# MSPM0G150X register map
Vendor: Texas Instruments; File version: This preliminary header file does not have a version number - build date: 2023-02-21 16:25:48
CPU: CM0 r0p1, little endian, MPU, no FPU, 3 interrupt priority bits
Registers are 32-bit, read-write, reset 0x0 unless marked. A register's access mark holds for its fields unless they carry their own. Offsets are from the block's base; [hi:lo] are bit positions.

## TRNG — PERIPHERALREGION
Base 0x40444000
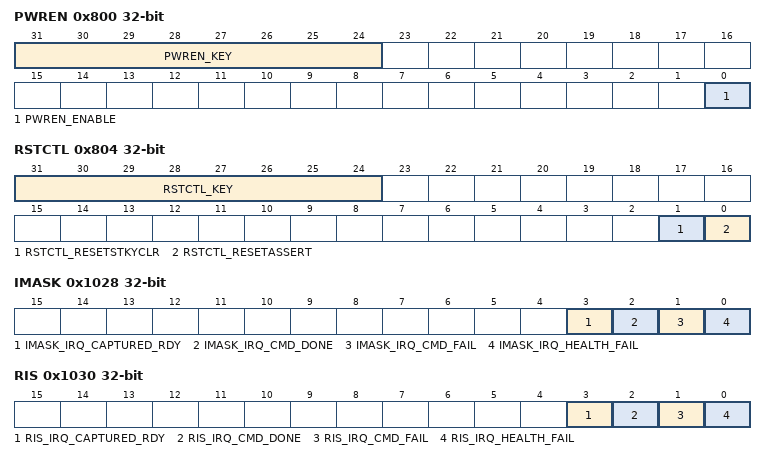
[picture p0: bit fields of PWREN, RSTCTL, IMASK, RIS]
0x800 PWREN — Power enable
  [31:24] PWREN_KEY wo — KEY to allow Power State Change
    38=PWREN_KEY_UNLOCK_W (_TO_UNLOCK_W_)
  [0] PWREN_ENABLE — Enable the power
    0=PWREN_ENABLE_DISABLE (DISABLE); 1=PWREN_ENABLE_ENABLE (ENABLE)
0x804 RSTCTL wo — Reset Control
  [31:24] RSTCTL_KEY — Unlock key
    177=RSTCTL_KEY_UNLOCK_W (_TO_UNLOCK_W_)
  [1] RSTCTL_RESETSTKYCLR — Clear the RESETSTKY bit in the STAT register
    0=RSTCTL_RESETSTKYCLR_NOP (NOP); 1=RSTCTL_RESETSTKYCLR_CLR (CLR)
  [0] RSTCTL_RESETASSERT — Assert reset to the peripheral
    0=RSTCTL_RESETASSERT_NOP (NOP); 1=RSTCTL_RESETASSERT_ASSERT (ASSERT)
0x814 GPRCM_STAT ro — Status Register
  [16] GPRCM_STAT_RESETSTKY — This bit indicates, if the peripheral was reset, since this bit was cleared by RESETSTKYCLR in the RSTCTL register
    0=GPRCM_STAT_RESETSTKY_NORES (NORES); 1=GPRCM_STAT_RESETSTKY_RESET (RESET)
0x1020 IIDX ro — Interrupt index
  [7:0] IIDX_STAT — Interrupt index status
    0=IIDX_STAT_NO_INTR (NO_INTR); 1=IIDX_STAT_IRQ_HEALTH_FAIL (IRQ_HEALTH_FAIL); 2=IIDX_STAT_IRQ_CMD_FAIL (IRQ_CMD_FAIL); 3=IIDX_STAT_IRQ_CMD_DONE (IRQ_CMD_DONE); 4=IIDX_STAT_IRQ_CAPTURED_RDY (IRQ_CAPTURED_RDY)
0x1028 IMASK — Interrupt mask
  [3] IMASK_IRQ_CAPTURED_RDY — Mask for IRQ_CAPTURED_RDY. Indicates to the CPU that the Captured Word is ready to be read.
    0=IMASK_IRQ_CAPTURED_RDY_DISABLED (DISABLED); 1=IMASK_IRQ_CAPTURED_RDY_ENABLED (ENABLED)
  [2] IMASK_IRQ_CMD_DONE — Mask for IRQ_CMD_DONE. Indicates that a command has finished
    0=IMASK_IRQ_CMD_DONE_DISABLED (DISABLED); 1=IMASK_IRQ_CMD_DONE_ENABLED (ENABLED)
  [1] IMASK_IRQ_CMD_FAIL — Masked interrupt source for IRQ_CMD_FAIL. Indicates that the just issued command/mode has been rejected.
    0=IMASK_IRQ_CMD_FAIL_DISABLED (DISABLED); 1=IMASK_IRQ_CMD_FAIL_ENABLED (ENABLED)
  [0] IMASK_IRQ_HEALTH_FAIL — Mask for IRQ_HEALTH_FAIL. Indicates that a health test has failed.
    0=IMASK_IRQ_HEALTH_FAIL_DISABLED (DISABLED); 1=IMASK_IRQ_HEALTH_FAIL_ENABLED (ENABLED)
0x1030 RIS ro — Raw interrupt status
  [3] RIS_IRQ_CAPTURED_RDY — Indicates to the CPU that the Captured Word is ready to be read. Reading the IIDX will clear this interrupt.
    0=RIS_IRQ_CAPTURED_RDY_CLR (CLR); 1=RIS_IRQ_CAPTURED_RDY_SET (SET)
  [2] RIS_IRQ_CMD_DONE — Raw interrupt source for IRQ_CMD_DONE. Indicates that the issued command/mode has completed.
    0=RIS_IRQ_CMD_DONE_CLR (CLR); 1=RIS_IRQ_CMD_DONE_SET (SET)
  [1] RIS_IRQ_CMD_FAIL — Masked interrupt source for IRQ_CMD_FAIL. Indicates that the just issued command/mode has been rejected.
    0=RIS_IRQ_CMD_FAIL_CLR (CLR); 1=RIS_IRQ_CMD_FAIL_SET (SET)
  [0] RIS_IRQ_HEALTH_FAIL — Indicates to the CPU that any of the health tests have failed. Reading the IIDX will clear this interrupt.
    0=RIS_IRQ_HEALTH_FAIL_CLR (CLR); 1=RIS_IRQ_HEALTH_FAIL_SET (SET)
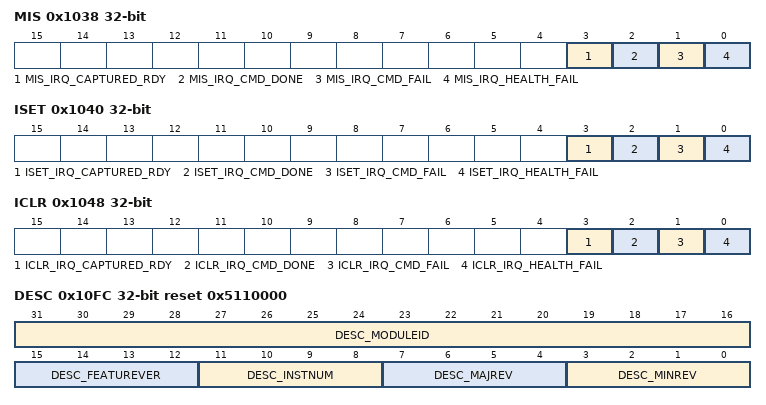
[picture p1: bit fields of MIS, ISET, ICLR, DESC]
0x1038 MIS ro — Masked interrupt status
  [3] MIS_IRQ_CAPTURED_RDY — Masked interrupt result for CAPTURED_READY. Indicates to the CPU that the Captured Word is ready to be read. Reading the IIDX will clear this interrupt.
    0=MIS_IRQ_CAPTURED_RDY_CLR (CLR); 1=MIS_IRQ_CAPTURED_RDY_SET (SET)
  [2] MIS_IRQ_CMD_DONE — Masked interrupt source for IRQ_CMD_DONE. Indicates that the issued command/mode has completed.
    0=MIS_IRQ_CMD_DONE_CLR (CLR); 1=MIS_IRQ_CMD_DONE_SET (SET)
  [1] MIS_IRQ_CMD_FAIL — Masked interrupt source for IRQ_CMD_FAIL. Indicates that the just issued command/mode has been rejected.
    0=MIS_IRQ_CMD_FAIL_CLR (CLR); 1=MIS_IRQ_CMD_FAIL_SET (SET)
  [0] MIS_IRQ_HEALTH_FAIL — Masked interrupt result for HEALTH_FAIL. Indicates to the CPU that any of the health tests have failed for the latest 1024-bit window.
    0=MIS_IRQ_HEALTH_FAIL_CLR (CLR); 1=MIS_IRQ_HEALTH_FAIL_SET (SET)
0x1040 ISET wo — Interrupt set
  [3] ISET_IRQ_CAPTURED_RDY — Indicates to the CPU that the Captured Word is ready to be read. Reading the IIDX or DATA_CAPTURE registers will clear this interrupt.
    0=ISET_IRQ_CAPTURED_RDY_NO_EFFECT (NO_EFFECT); 1=ISET_IRQ_CAPTURED_RDY_SET (SET)
  [2] ISET_IRQ_CMD_DONE — Write to turn on CMD_DONE IRQ. Indicates that the last issued TRNG command has finished.
    0=ISET_IRQ_CMD_DONE_NO_EFFECT (NO_EFFECT); 1=ISET_IRQ_CMD_DONE_SET (SET)
  [1] ISET_IRQ_CMD_FAIL — Masked interrupt source for IRQ_CMD_FAIL. Indicates that the just issued command/mode has been rejected.
    0=ISET_IRQ_CMD_FAIL_NO_EFFECT (NO_EFFECT); 1=ISET_IRQ_CMD_FAIL_SET (SET)
  [0] ISET_IRQ_HEALTH_FAIL — Indicates to the CPU that any of the health tests have failed. Reading the IIDX or DATA_CAPTURE registers will clear this interrupt.
    0=ISET_IRQ_HEALTH_FAIL_NO_EFFECT (NO_EFFECT); 1=ISET_IRQ_HEALTH_FAIL_SET (SET)
0x1048 ICLR wo — Interrupt clear
  [3] ICLR_IRQ_CAPTURED_RDY — Indicates to the CPU that the Captured Word is ready to be read. Reading the IIDX or DATA_CAPTURE registers will clear this interrupt.
    0=ICLR_IRQ_CAPTURED_RDY_NO_EFFECT (NO_EFFECT); 1=ICLR_IRQ_CAPTURED_RDY_CLR (CLR)
  [2] ICLR_IRQ_CMD_DONE — Write to turn off CMD_DONE IRQ. Indicates that the last issued TRNG command has finished.
    0=ICLR_IRQ_CMD_DONE_NO_EFFECT (NO_EFFECT); 1=ICLR_IRQ_CMD_DONE_CLR (CLR)
  [1] ICLR_IRQ_CMD_FAIL — Masked interrupt source for IRQ_CMD_FAIL. Indicates that the just issued command/mode has been rejected.
    0=ICLR_IRQ_CMD_FAIL_NO_EFFECT (NO_EFFECT); 1=ICLR_IRQ_CMD_FAIL_CLR (CLR)
  [0] ICLR_IRQ_HEALTH_FAIL — Indicates to the CPU that any of the health tests have failed. Reading the IIDX or DATA_CAPTURE registers will clear this interrupt.
    0=ICLR_IRQ_HEALTH_FAIL_NO_EFFECT (NO_EFFECT); 1=ICLR_IRQ_HEALTH_FAIL_CLR (CLR)
0x10FC DESC ro reset 0x5110000 — Module descriptions
  [31:16] DESC_MODULEID — Module Identifier - An internal TI page has been created to request unique module IDs
  [15:12] DESC_FEATUREVER — Feature Set for the module *instance*
  [11:8] DESC_INSTNUM — Instance Number within the device. This will be a parameter to the RTL for modules that can have multiple instances
  [7:4] DESC_MAJREV — Major rev of the IP
  [3:0] DESC_MINREV — Minor rev of the IP
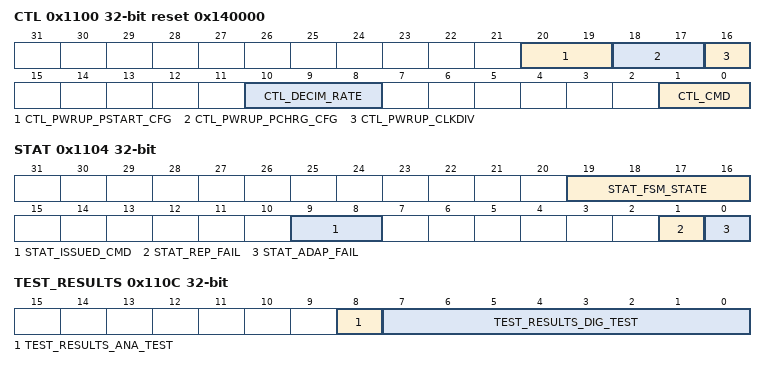
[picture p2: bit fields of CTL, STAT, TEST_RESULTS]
0x1100 CTL reset 0x140000 — Controls the command and decimation rate
  [20:19] CTL_PWRUP_PSTART_CFG — Configure pusle startup sequence length b00 = Disabled b01 = rise at 10us, fall at 50us b10 = rise at 10us, fall at 70us (default) b11 = rise at 10us, fall at 90us
  [18:17] CTL_PWRUP_PCHRG_CFG — Configure PCHARGE sequence length b00 = Disabled b01 = 20 us PCHARGE b10 = 30 us PCHARGE (default) b11 = 40 us PCHARGE
  [16] CTL_PWRUP_CLKDIV — When '1', the powerup sequence will take twice as long (i.e., clock frequency halved)
  [10:8] CTL_DECIM_RATE — Set decimation rate. Decimate by n 0x0 = Decimation by 1 (no decimation) 0x1 = Decimation by 2 (Skip every other sample) 0x7 = Decimation by 8 (Take every 8th sample)
  [1:0] CTL_CMD — Sets the TRNG mode through a command. The mode will not be updated until the previous command is done, as indicated by IRQ_CMD_DONE. 00 --> OFF 01 --> PWRUP_DIG 10 --> PWRUP_ANA 11 --> NORM_FUNC
    0=CTL_CMD_PWR_OFF (PWR_OFF); 1=CTL_CMD_PWRUP_DIG (PWRUP_DIG); 2=CTL_CMD_PWRUP_ANA (PWRUP_ANA); 3=CTL_CMD_NORM_FUNC (NORM_FUNC)
0x1104 STAT ro — Status register that informs health test results and last issued command
  [19:16] STAT_FSM_STATE — Current state of the front end FSM (behind a clock domain crossing). 2 reads are REQUIRED as there is a chance of metastability when reading this States: 0000: OFF 0001: PWRUP_ES 0011: NORM_FUNC 0111: TEST_DIG 1011: TEST_ANA 1010: ERROR 0010: PWRDOWN_ES
  [9:8] STAT_ISSUED_CMD — Indicates the last accepted command that is issued to the TRNG interface. Upon writing a valid command, this register will update and the command will be in progress until CMD_DONE_IRQ is set. CMD_DONE_IRQ indicates that the state is in PWROFF, NORM_FUNC, or ERROR. These states will accept new commands. 00 --> OFF 01 --> PWRUP_DIG 10 --> PWRUP_ANA 11 --> NORM_FUNC
  [1] STAT_REP_FAIL — Indicates that the repetition counter test caused the most recent failure. Thus, the health count numbers are most likely not for a complete 1024-bit window.
  [0] STAT_ADAP_FAIL — Indicates that the Adaptive Proportion Test (1,2,3, or 4-bit counters) failed by having too many or too few counted samples in the last 1024 bit window.
0x1108 DATA_CAPTURE ro — Captured word buffer of RNG data
  [31:0] DATA_CAPTURE_BUFFER — Captured Data from the Decimation Block
0x110C TEST_RESULTS ro — Test results from TEST_ANA and TEST_DIG
  [8] TEST_RESULTS_ANA_TEST — Runs through 4096 samples from an enabled entropy source and verifies that none of the health tests failed, indicating sufficient entropy was produced by the analog components
  [7:0] TEST_RESULTS_DIG_TEST — Bit 0 indicates if the first decimation rate test and health test(verifies conditioning, decimation, and captured buffer) fails and Bit 1 indicates if the second decimation test and health test fails Bit 0 - decim_test0 (decim = 0x0) Bit 1 - decim_test1 (decim = 0x1) ...
0x1110 CLKDIVIDE — Clock Divider
  [2:0] CLKDIVIDE_RATIO — Selects divide ratio of module clock
    0=CLKDIVIDE_RATIO_DIV_BY_1 (DIV_BY_1); 1=CLKDIVIDE_RATIO_DIV_BY_2 (DIV_BY_2); 3=CLKDIVIDE_RATIO_DIV_BY_4 (DIV_BY_4); 5=CLKDIVIDE_RATIO_DIV_BY_6 (DIV_BY_6); 7=CLKDIVIDE_RATIO_DIV_BY_8 (DIV_BY_8)
